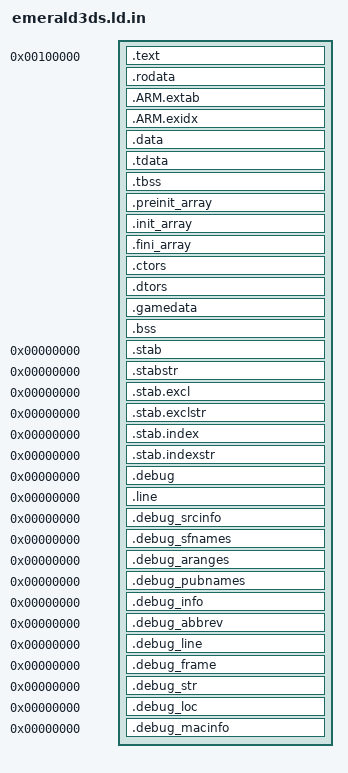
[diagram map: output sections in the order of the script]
/*--------------------------------------------------------------------------------
	This Source Code Form is subject to the terms of the Mozilla Public License,
	v. 2.0. If a copy of the MPL was not distributed with this file, You can
	obtain one at https://mozilla.org/MPL/2.0/.
--------------------------------------------------------------------------------*/
/*
	Emerald3DS: devkitARM's 3dsx.ld with two additions. The game's own
	variables lead .data and .bss, between __ctr_game_* symbols (for the soft
	reset, see .data). The read-only data of
	the game translation units (build/root/src, build/root/data) leaves .rodata
	and is gathered in .gamedata, at the end of the data segment. The Makefile
	generates two scripts from this template that differ only in @GAMEDATA_TYPE@:
	the image link keeps the section's contents so they can be extracted, and
	the shipped executable reserves it as NOLOAD; the bytes arrive from the data
	pack at start-up (3ds_port/scripts/gen_gamedata_bundle.py).
*/
OUTPUT_FORMAT("elf32-littlearm", "elf32-bigarm", "elf32-littlearm")
OUTPUT_ARCH(arm)
ENTRY(_start)

PHDRS
{
	code   PT_LOAD FLAGS(5) /* Read | Execute */;
	rodata PT_LOAD FLAGS(4) /* Read */;
	data   PT_LOAD FLAGS(6) /* Read | Write */;
}

SECTIONS
{
	/* =========== CODE section =========== */

	PROVIDE(__start__ = 0x100000);
	. = __start__;

	.text ALIGN(0x1000) :
	{
		/* The code the boot log identifies by its hash (3ds_prof.c). */
		__ctr_text_start = .;
		/* .init */
		KEEP( *(.crt0) )
		KEEP( *(.init) )
		. = ALIGN(4);

		/* .text */
		*(.text)
		*(.text.*)
		*(.glue_7)
		*(.glue_7t)
		*(.stub)
		*(.gnu.warning)
		*(.gnu.linkonce.t*)
		. = ALIGN(4);

		/* .fini */
		KEEP( *(.fini) )
		. = ALIGN(4);
		__ctr_text_end = .;
	} : code

	/* =========== RODATA section =========== */

	. = ALIGN(0x1000);

	.rodata :
	{
		EXCLUDE_FILE(*build/root/src/* *build/root/data/*) *(.rodata .roda .rodata.*)
		/* Port code in the game tree and the port's map descriptors. */
		*build/root/src/platform/*(.rodata .roda .rodata.*)
		*(.rodata.port_map_assets)
		*all.rodata*(*)
		*(.gnu.linkonce.r*)
		SORT(CONSTRUCTORS)
		. = ALIGN(4);
		__tdata_align = .;
		LONG (ALIGNOF(.tdata));
		. = ALIGN(4);
	} : rodata

	.ARM.extab : { *(.ARM.extab* .gnu.linkonce.armextab.*) } : rodata
	__exidx_start = .;
	.ARM.exidx : { *(.ARM.exidx* .gnu.linkonce.armexidx.*) } : rodata
	__exidx_end = .;

	/* =========== DATA section =========== */

	. = ALIGN(0x1000);

	.data :
	{
		/* The game's own variables (not its platform/ layer, which holds the
		   emulated hardware and the flash with the save) come first and
		   together, here and in .bss: 3ds_game_full.c keeps a copy of them as
		   AgbMain first starts and puts it back for a soft reset, as the GBA
		   clears its RAM. */
		__ctr_game_data = .;
		EXCLUDE_FILE(*build/root/src/platform/*) *build/root/src/*(.data .data.*)
		*build/root/data/*(.data .data.*)
		. = ALIGN(4);
		__ctr_game_data_end = .;
		*(.data)
		*(.data.*)
		*(.gnu.linkonce.d*)
		CONSTRUCTORS
		. = ALIGN(4);
	} : data

	.tdata : ALIGN(4)
	{
		__tdata_lma = .;
		*(.tdata)
		*(.tdata.*)
		*(.gnu.linkonce.td.*)
		. = ALIGN(4);
		__tdata_lma_end = .;
	} : data

	.tbss : ALIGN(4)
	{
		*(.tbss)
		*(.tbss.*)
		*(.gnu.linkonce.tb.*)
		*(.tcommon)
		. = ALIGN(4);
	} : data

	/*
    __tdata_align_val = ABSOLUTE(ALIGNOF(.tdata));
    __tdata_size = ABSOLUTE(SIZEOF(.tdata));
    __tbss_align = ABSOLUTE(ALIGNOF(.tbss));
    __tbss_size = ABSOLUTE(SIZEOF(.tbss));
	*/

	.preinit_array ALIGN(4) :
	{
		PROVIDE (__preinit_array_start = .);
		KEEP (*(.preinit_array))
		PROVIDE (__preinit_array_end = .);
	} : data

	.init_array ALIGN(4) :
	{
		PROVIDE (__init_array_start = .);
		KEEP (*(SORT(.init_array.*)))
		KEEP (*(.init_array))
		PROVIDE (__init_array_end = .);
	} : data

	.fini_array ALIGN(4) :
	{
		PROVIDE (__fini_array_start = .);
		KEEP (*(.fini_array))
		KEEP (*(SORT(.fini_array.*)))
		PROVIDE (__fini_array_end = .);
	} : data

	.ctors ALIGN(4) :
	{
		KEEP (*crtbegin.o(.ctors)) /* MUST be first -- GCC requires it */
		KEEP (*(EXCLUDE_FILE (*crtend.o) .ctors))
		KEEP (*(SORT(.ctors.*)))
		KEEP (*(.ctors))
	} : data

	.dtors ALIGN(4) :
	{
		KEEP (*crtbegin.o(.dtors))
		KEEP (*(EXCLUDE_FILE (*crtend.o) .dtors))
		KEEP (*(SORT(.dtors.*)))
		KEEP (*(.dtors))
	} : data

	.gamedata ALIGN(32) @GAMEDATA_TYPE@ :
	{
		__ctr_gamedata = .;
		*build/root/src/*(.rodata .roda .rodata.*)
		*build/root/data/*(.rodata .roda .rodata.*)
		. = ALIGN(4);
		__ctr_gamedata_end = .;
	} : data

	__bss_start__ = .;
	.bss ALIGN(4) :
	{
		/* The game's own variables: see .data. */
		__ctr_game_bss = .;
		/* Juan's defeat text is longer than gDisplayedStringBattle[300] (more so
		   in French and German). On the GBA it ran into an unused array; here it
		   hit live variables and crashed after the battle, so leave room behind it. */
		*build/root/src/battle_main.o(.bss.gDisplayedStringBattle)
		. += 1024;
		EXCLUDE_FILE(*build/root/src/platform/*) *build/root/src/*(.bss .bss.* COMMON)
		*build/root/data/*(.bss .bss.* COMMON)
		. = ALIGN(4);
		__ctr_game_bss_end = .;
		*(.dynbss)
		*(.bss)
		*(.bss.*)
		*(.gnu.linkonce.b*)
		*(COMMON)

		/* Reserve space for the TLS segment of the main thread.
		   We need (__tls_start - 8) to be aligned the same as .tdata, to account for
		   the 8-byte ARM TLS header. Since the header is not actually used for
		   ARM_TLS_LE32 relocation, we just fake it by subtracting 8 from the data
		   offset.
		 */
		. = 8 + ABSOLUTE(ALIGN(ABSOLUTE(. - 8), MAX(ALIGNOF(.tdata), ALIGNOF(.tbss))));
		__tls_start = .;
		. += SIZEOF(.tdata);

        /* Ensure the alignment of .tbss is accounted for in the total size,
           since SIZEOF(.tdata) doesn't include any padding before .tbss.
         */
        . = ALIGN(ALIGNOF(.tbss));
        . += SIZEOF(.tbss);
		__tls_end = .;
	} : data
	__bss_end__ = .;

	__end__ = ABSOLUTE(.) ;

	/* ==================
	   ==== Metadata ====
	   ================== */

	/* Discard sections that difficult post-processing */
	/DISCARD/ : { *(.group .comment .note) }

	/* Stabs debugging sections. */
	.stab          0 : { *(.stab) }
	.stabstr       0 : { *(.stabstr) }
	.stab.excl     0 : { *(.stab.excl) }
	.stab.exclstr  0 : { *(.stab.exclstr) }
	.stab.index    0 : { *(.stab.index) }
	.stab.indexstr 0 : { *(.stab.indexstr) }

	/* DWARF debug sections.
	   Symbols in the DWARF debugging sections are relative to the beginning
	   of the section so we begin them at 0. */

	/* DWARF 1 */
	.debug          0 : { *(.debug) }
	.line           0 : { *(.line) }

	/* GNU DWARF 1 extensions */
	.debug_srcinfo  0 : { *(.debug_srcinfo) }
	.debug_sfnames  0 : { *(.debug_sfnames) }

	/* DWARF 1.1 and DWARF 2 */
	.debug_aranges  0 : { *(.debug_aranges) }
	.debug_pubnames 0 : { *(.debug_pubnames) }

	/* DWARF 2 */
	.debug_info     0 : { *(.debug_info) }
	.debug_abbrev   0 : { *(.debug_abbrev) }
	.debug_line     0 : { *(.debug_line) }
	.debug_frame    0 : { *(.debug_frame) }
	.debug_str      0 : { *(.debug_str) }
	.debug_loc      0 : { *(.debug_loc) }
	.debug_macinfo  0 : { *(.debug_macinfo) }
}
